# LPC811 register map
Vendor: nxp.com; File version: 1.0
CPU: CM0PLUS r0p0, little endian, no MPU, no FPU, VTOR, 2 interrupt priority bits
Registers are 32-bit, read-write, reset 0x0 unless marked. A register's access mark holds for its fields unless they carry their own. Offsets are from the block's base; [hi:lo] are bit positions; {n}, {i} and the like mark numbered series.

## CRC — LPC5411x CRC engine
Base 0x50000000
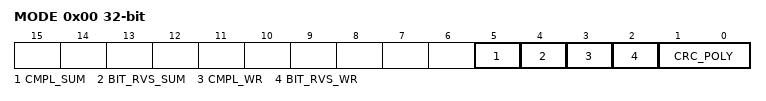
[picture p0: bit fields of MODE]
0x00 MODE — CRC mode register
  [5] CMPL_SUM — CRC sum complement: 1 = 1's complement for CRC_SUM 0 = No 1's complement for CRC_SUM
  [4] BIT_RVS_SUM — CRC sum bit order: 1 = Bit order reverse for CRC_SUM 0 = No bit order reverse for CRC_SUM
  [3] CMPL_WR — Data complement: 1 = 1's complement for CRC_WR_DATA 0 = No 1's complement for CRC_WR_DATA
  [2] BIT_RVS_WR — Data bit order: 1 = Bit order reverse for CRC_WR_DATA (per byte) 0 = No bit order reverse for CRC_WR_DATA (per byte)
  [1:0] CRC_POLY — CRC polynomial: 1X = CRC-32 polynomial 01 = CRC-16 polynomial 00 = CRC-CCITT polynomial
0x04 SEED reset 0xFFFF — CRC seed register
  [31:0] CRC_SEED — A write access to this register will load CRC seed value to CRC_SUM register with selected bit order and 1's complement pre-processes. A write access to this register will overrule the CRC calculation in progresses.
0x08 SUM ro reset 0xFFFF (SUM_WR_DATA view) — CRC checksum register
  [31:0] CRC_SUM — The most recent CRC sum can be read through this register with selected bit order and 1's complement post-processes.
0x08 WR_DATA wo reset not defined (SUM_WR_DATA view) — CRC data register
  [31:0] CRC_WR_DATA — Data written to this register will be taken to perform CRC calculation with selected bit order and 1's complement pre-process. Any write size 8, 16 or 32-bit are allowed and accept back-to-back transactions.

## GPIO — General Purpose I/O (GPIO)
Base 0xA0000000
{0x0+i} B0_{i} 8-bit (i=0..17) — Byte pin registers for all port 0 and 1 GPIO pins
  [0] PBYTE — Read: state of the pin PIOm_n, regardless of direction, masking, or alternate function, except that pins configured as analog I/O always read as 0. One register for each port pin. Supported pins depends on the specific device and package. Write: loads the pin's output bit. One register for each port pin. Supported pins depends on the specific device and package.
{0x1000+4i} W0_{i} (i=0..17) — Word pin registers for all port 0 and 1 GPIO pins
  [31:0] PWORD — Read 0: pin PIOm_n is LOW. Write 0: clear output bit. Read 0xFFFF FFFF: pin PIOm_n is HIGH. Write any value 0x0000 0001 to 0xFFFF FFFF: set output bit. Only 0 or 0xFFFF FFFF can be read. Writing any value other than 0 will set the output bit. One register for each port pin. Supported pins depends on the specific device and package.
0x2000 DIR0 — Direction registers
  [17:0] DIRP — Selects pin direction for pin PIOm_n (bit 0 = PIOn_0, bit 1 = PIOn_1, etc.). Supported pins depends on the specific device and package. 0 = input. 1 = output.
0x2080 MASK0 — Mask register
  [17:0] MASKP — Controls which bits corresponding to PIOm_n are active in the MPORT register (bit 0 = PIOn_0, bit 1 = PIOn_1, etc.). Supported pins depends on the specific device and package. 0 = Read MPORT: pin state; write MPORT: load output bit. 1 = Read MPORT: 0; write MPORT: output bit not affected.
0x2100 PIN0 — Port pin register
  [17:0] PORT — Reads pin states or loads output bits (bit 0 = PIOn_0, bit 1 = PIOn_1, etc.). Supported pins depends on the specific device and package. 0 = Read: pin is low; write: clear output bit. 1 = Read: pin is high; write: set output bit.
0x2180 MPIN0 — Masked port register
  [17:0] MPORTP — Masked port register (bit 0 = PIOn_0, bit 1 = PIOn_1, etc.). Supported pins depends on the specific device and package. 0 = Read: pin is LOW and/or the corresponding bit in the MASK register is 1; write: clear output bit if the corresponding bit in the MASK register is 0. 1 = Read: pin is HIGH and the corresponding bit in the MASK register is 0; write: set output bit if the corresponding bit in the MASK register is 0.
0x2200 SET0 — Write: Set register for port Read: output bits for port
  [17:0] SETP — Read or set output bits (bit 0 = PIOn_0, bit 1 = PIOn_1, etc.). Supported pins depends on the specific device and package. 0 = Read: output bit: write: no operation. 1 = Read: output bit; write: set output bit.
0x2280 CLR0 wo reset not defined — Clear port
  [17:0] CLRP — Clear output bits (bit 0 = PIOn_0, bit 1 = PIOn_1, etc.). Supported pins depends on the specific device and package. 0 = No operation. 1 = Clear output bit.
0x2300 NOT0 wo reset not defined — Toggle port
  [17:0] NOTP — Toggle output bits (bit 0 = PIOn_0, bit 1 = PIOn_1, etc.). Supported pins depends on the specific device and package. 0 = no operation. 1 = Toggle output bit.
